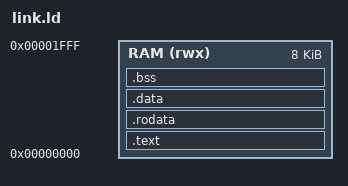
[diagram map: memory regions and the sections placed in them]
MEMORY { RAM (rwx) : ORIGIN = 0x0, LENGTH = 8K }
SECTIONS {
  .text : { *(.text.start) *(.text*) } > RAM
  .rodata : { *(.rodata*) *(.srodata*) } > RAM
  .data : { *(.data*) *(.sdata*) } > RAM
  .bss : { *(.bss*) *(.sbss*) *(COMMON) } > RAM
  _end = .;
}
